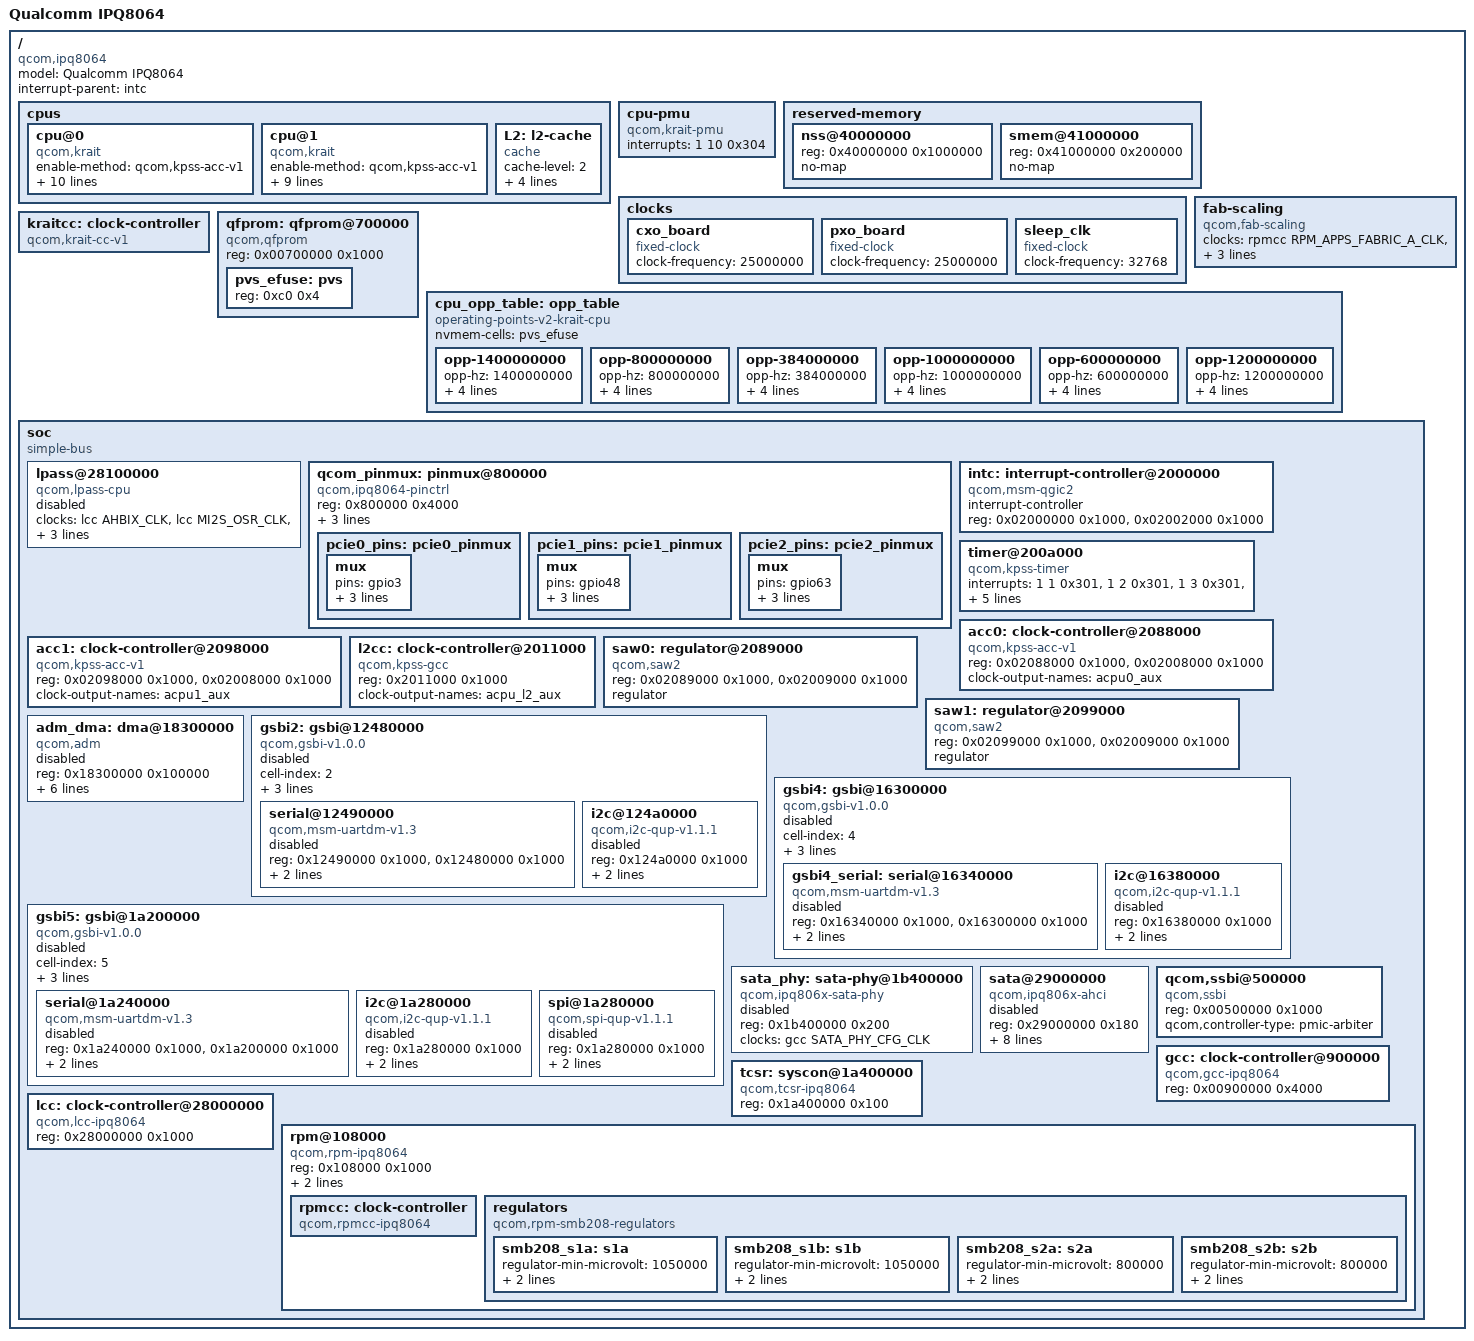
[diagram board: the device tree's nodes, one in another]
/dts-v1/;

#include "skeleton.dtsi"
#include <dt-bindings/clock/qcom,gcc-ipq806x.h>
#include <dt-bindings/clock/qcom,lcc-ipq806x.h>
#include <dt-bindings/reset/qcom,gcc-ipq806x.h>
#include <dt-bindings/soc/qcom,gsbi.h>
#include <dt-bindings/interrupt-controller/arm-gic.h>
#include <dt-bindings/reset/qcom,gcc-ipq806x.h>
#include <dt-bindings/gpio/gpio.h>
#include <dt-bindings/mfd/qcom-rpm.h>
#include <dt-bindings/clock/qcom,rpmcc.h>
/ {
	model = "Qualcomm IPQ8064";
	compatible = "qcom,ipq8064";
	interrupt-parent = <&intc>;

	cpus {
		#address-cells = <1>;
		#size-cells = <0>;

		cpu@0 {
			compatible = "qcom,krait";
			enable-method = "qcom,kpss-acc-v1";
			device_type = "cpu";
			reg = <0>;
			next-level-cache = <&L2>;
			qcom,acc = <&acc0>;
			qcom,saw = <&saw0>;
			clocks = <&kraitcc 0>;
			clock-names = "cpu";
			clock-latency = <100000>;
			cpu-supply = <&smb208_s2a>;
			voltage-tolerance = <5>;
			cpu_fab_threshold = <1000000000>;
			operating-points-v2 = <&cpu_opp_table>;
		};

		cpu@1 {
			compatible = "qcom,krait";
			enable-method = "qcom,kpss-acc-v1";
			device_type = "cpu";
			reg = <1>;
			next-level-cache = <&L2>;
			qcom,acc = <&acc1>;
			qcom,saw = <&saw1>;
			clocks = <&kraitcc 1>;
			clock-names = "cpu";
			clock-latency = <100000>;
			cpu-supply = <&smb208_s2b>;
			cpu_fab_threshold = <1000000000>;
			operating-points-v2 = <&cpu_opp_table>;
		};

		L2: l2-cache {
			compatible = "cache";
			cache-level = <2>;
			clocks = <&kraitcc 4>;
			clock-names = "cache";
			cache-points-kHz = <
				/* kHz    uV    CPU kHz */
				1200000 1150000 1200000
				1000000 1100000  600000
				 384000 1100000  384000
			>;
			vdd_dig-supply = <&smb208_s1a>;
		};
	};

	cpu-pmu {
		compatible = "qcom,krait-pmu";
		interrupts = <1 10 0x304>;
	};

	reserved-memory {
		#address-cells = <1>;
		#size-cells = <1>;
		ranges;

		nss@40000000 {
			reg = <0x40000000 0x1000000>;
			no-map;
		};

		smem@41000000 {
			reg = <0x41000000 0x200000>;
			no-map;
		};
	};

	clocks {
		cxo_board {
			compatible = "fixed-clock";
			#clock-cells = <0>;
			clock-frequency = <25000000>;
		};

		pxo_board {
			compatible = "fixed-clock";
			#clock-cells = <0>;
			clock-frequency = <25000000>;
		};

		sleep_clk: sleep_clk {
			compatible = "fixed-clock";
			clock-frequency = <32768>;
			#clock-cells = <0>;
		};
	};

	fab-scaling {
		compatible = "qcom,fab-scaling";
		clocks = <&rpmcc RPM_APPS_FABRIC_A_CLK>, <&rpmcc RPM_EBI1_A_CLK>;
		clock-names = "apps-fab-clk", "ddr-fab-clk";
		fab_freq_high = <533000000>;
		fab_freq_nominal = <400000000>;
	};

	kraitcc: clock-controller {
		compatible = "qcom,krait-cc-v1";
		#clock-cells = <1>;
	};

	qfprom: qfprom@700000 {
		compatible      = "qcom,qfprom";
		reg	     = <0x00700000 0x1000>;
		#address-cells  = <1>;
		#size-cells     = <1>;
		ranges;
		/* len = 0x4 for FORMAT A */
		pvs_efuse: pvs {
			reg = <0xc0 0x4>;
		};
	};

	cpu_opp_table: opp_table {
		compatible = "operating-points-v2-krait-cpu";
		nvmem-cells = <&pvs_efuse>;

		/*
		 * Missing opp-shared property means CPUs switch DVFS states
		 * independently.
		 */

		opp-1400000000 {
			opp-hz = /bits/ 64 <1400000000>;
			opp-microvolt-speed0-pvs0-v0 = <1250000>;
			opp-microvolt-speed0-pvs1-v0 = <1175000>;
			opp-microvolt-speed0-pvs2-v0 = <1125000>;
			opp-microvolt-speed0-pvs3-v0 = <1050000>;
		};

		opp-800000000 {
			opp-hz = /bits/ 64 <800000000>;
			opp-microvolt-speed0-pvs0-v0 = <1100000>;
			opp-microvolt-speed0-pvs1-v0 = <1025000>;
			opp-microvolt-speed0-pvs2-v0 = <995000>;
			opp-microvolt-speed0-pvs3-v0 = <900000>;
		};

		opp-384000000 {
			opp-hz = /bits/ 64 <384000000>;
			opp-microvolt-speed0-pvs0-v0 = <1000000>;
			opp-microvolt-speed0-pvs1-v0 = <925000>;
			opp-microvolt-speed0-pvs2-v0 = <875000>;
			opp-microvolt-speed0-pvs3-v0 = <800000>;
		};

		opp-1000000000 {
			opp-hz = /bits/ 64 <1000000000>;
			opp-microvolt-speed0-pvs0-v0 = <1150000>;
			opp-microvolt-speed0-pvs1-v0 = <1075000>;
			opp-microvolt-speed0-pvs2-v0 = <1025000>;
			opp-microvolt-speed0-pvs3-v0 = <950000>;
		};

		opp-600000000 {
			opp-hz = /bits/ 64 <600000000>;
			opp-microvolt-speed0-pvs0-v0 = <1050000>;
			opp-microvolt-speed0-pvs1-v0 = <975000>;
			opp-microvolt-speed0-pvs2-v0 = <925000>;
			opp-microvolt-speed0-pvs3-v0 = <850000>;
		};

		opp-1200000000 {
			opp-hz = /bits/ 64 <1200000000>;
			opp-microvolt-speed0-pvs0-v0 = <1200000>;
			opp-microvolt-speed0-pvs1-v0 = <1125000>;
			opp-microvolt-speed0-pvs2-v0 = <1075000>;
			opp-microvolt-speed0-pvs3-v0 = <1000000>;
		};
	};

	soc: soc {
		#address-cells = <1>;
		#size-cells = <1>;
		ranges;
		compatible = "simple-bus";

		lpass@28100000 {
			compatible = "qcom,lpass-cpu";
			status = "disabled";
			clocks = <&lcc AHBIX_CLK>,
					<&lcc MI2S_OSR_CLK>,
					<&lcc MI2S_BIT_CLK>;
			clock-names = "ahbix-clk",
					"mi2s-osr-clk",
					"mi2s-bit-clk";
			interrupts = <0 85 1>;
			interrupt-names = "lpass-irq-lpaif";
			reg = <0x28100000 0x10000>;
			reg-names = "lpass-lpaif";
		};

		qcom_pinmux: pinmux@800000 {
			compatible = "qcom,ipq8064-pinctrl";
			reg = <0x800000 0x4000>;

			gpio-controller;
			#gpio-cells = <2>;
			interrupt-controller;
			#interrupt-cells = <2>;
			interrupts = <0 16 0x4>;

			pcie0_pins: pcie0_pinmux {
				mux {
					pins = "gpio3";
					function = "pcie1_rst";
					drive-strength = <12>;
					bias-disable;
				};
			};

			pcie1_pins: pcie1_pinmux {
				mux {
					pins = "gpio48";
					function = "pcie2_rst";
					drive-strength = <12>;
					bias-disable;
				};
			};

			pcie2_pins: pcie2_pinmux {
				mux {
					pins = "gpio63";
					function = "pcie3_rst";
					drive-strength = <12>;
					bias-disable;
				};
			};
		};

		intc: interrupt-controller@2000000 {
			compatible = "qcom,msm-qgic2";
			interrupt-controller;
			#interrupt-cells = <3>;
			reg = <0x02000000 0x1000>,
			      <0x02002000 0x1000>;
		};

		timer@200a000 {
			compatible = "qcom,kpss-timer",
				     "qcom,kpss-wdt-ipq8064", "qcom,msm-timer";
			interrupts = <1 1 0x301>,
				     <1 2 0x301>,
				     <1 3 0x301>,
				     <1 4 0x301>,
				     <1 5 0x301>;
			reg = <0x0200a000 0x100>;
			clock-frequency = <25000000>,
					  <32768>;
			clocks = <&sleep_clk>;
			clock-names = "sleep";
			cpu-offset = <0x80000>;
		};

		acc0: clock-controller@2088000 {
			compatible = "qcom,kpss-acc-v1";
			reg = <0x02088000 0x1000>, <0x02008000 0x1000>;
			clock-output-names = "acpu0_aux";
		};

		acc1: clock-controller@2098000 {
			compatible = "qcom,kpss-acc-v1";
			reg = <0x02098000 0x1000>, <0x02008000 0x1000>;
			clock-output-names = "acpu1_aux";
		};

		l2cc: clock-controller@2011000 {
			compatible = "qcom,kpss-gcc", "syscon";
			reg = <0x2011000 0x1000>;
			clock-output-names = "acpu_l2_aux";
		};

		saw0: regulator@2089000 {
			compatible = "qcom,saw2";
			reg = <0x02089000 0x1000>, <0x02009000 0x1000>;
			regulator;
		};

		saw1: regulator@2099000 {
			compatible = "qcom,saw2";
			reg = <0x02099000 0x1000>, <0x02009000 0x1000>;
			regulator;
		};

		adm_dma: dma@18300000 {
			compatible = "qcom,adm";
			reg = <0x18300000 0x100000>;
			interrupts = <0 170 0>;
			#dma-cells = <1>;

			clocks = <&gcc ADM0_CLK>, <&gcc ADM0_PBUS_CLK>;
			clock-names = "core", "iface";

			resets = <&gcc ADM0_RESET>,
				 <&gcc ADM0_PBUS_RESET>,
				 <&gcc ADM0_C0_RESET>,
				 <&gcc ADM0_C1_RESET>,
				 <&gcc ADM0_C2_RESET>;
			reset-names = "clk", "pbus", "c0", "c1", "c2";
			qcom,ee = <0>;

			status = "disabled";
		};

		gsbi2: gsbi@12480000 {
			compatible = "qcom,gsbi-v1.0.0";
			cell-index = <2>;
			reg = <0x12480000 0x100>;
			clocks = <&gcc GSBI2_H_CLK>;
			clock-names = "iface";
			#address-cells = <1>;
			#size-cells = <1>;
			ranges;
			status = "disabled";

			syscon-tcsr = <&tcsr>;

			serial@12490000 {
				compatible = "qcom,msm-uartdm-v1.3", "qcom,msm-uartdm";
				reg = <0x12490000 0x1000>,
				      <0x12480000 0x1000>;
				interrupts = <0 195 0x0>;
				clocks = <&gcc GSBI2_UART_CLK>, <&gcc GSBI2_H_CLK>;
				clock-names = "core", "iface";
				status = "disabled";
			};

			i2c@124a0000 {
				compatible = "qcom,i2c-qup-v1.1.1";
				reg = <0x124a0000 0x1000>;
				interrupts = <0 196 0>;

				clocks = <&gcc GSBI2_QUP_CLK>, <&gcc GSBI2_H_CLK>;
				clock-names = "core", "iface";
				status = "disabled";

				#address-cells = <1>;
				#size-cells = <0>;
			};

		};

		gsbi4: gsbi@16300000 {
			compatible = "qcom,gsbi-v1.0.0";
			cell-index = <4>;
			reg = <0x16300000 0x100>;
			clocks = <&gcc GSBI4_H_CLK>;
			clock-names = "iface";
			#address-cells = <1>;
			#size-cells = <1>;
			ranges;
			status = "disabled";

			syscon-tcsr = <&tcsr>;

			gsbi4_serial: serial@16340000 {
				compatible = "qcom,msm-uartdm-v1.3", "qcom,msm-uartdm";
				reg = <0x16340000 0x1000>,
				      <0x16300000 0x1000>;
				interrupts = <0 152 0x0>;
				clocks = <&gcc GSBI4_UART_CLK>, <&gcc GSBI4_H_CLK>;
				clock-names = "core", "iface";
				status = "disabled";
			};

			i2c@16380000 {
				compatible = "qcom,i2c-qup-v1.1.1";
				reg = <0x16380000 0x1000>;
				interrupts = <0 153 0>;

				clocks = <&gcc GSBI4_QUP_CLK>, <&gcc GSBI4_H_CLK>;
				clock-names = "core", "iface";
				status = "disabled";

				#address-cells = <1>;
				#size-cells = <0>;
			};
		};

		gsbi5: gsbi@1a200000 {
			compatible = "qcom,gsbi-v1.0.0";
			cell-index = <5>;
			reg = <0x1a200000 0x100>;
			clocks = <&gcc GSBI5_H_CLK>;
			clock-names = "iface";
			#address-cells = <1>;
			#size-cells = <1>;
			ranges;
			status = "disabled";

			syscon-tcsr = <&tcsr>;

			serial@1a240000 {
				compatible = "qcom,msm-uartdm-v1.3", "qcom,msm-uartdm";
				reg = <0x1a240000 0x1000>,
				      <0x1a200000 0x1000>;
				interrupts = <0 154 0x0>;
				clocks = <&gcc GSBI5_UART_CLK>, <&gcc GSBI5_H_CLK>;
				clock-names = "core", "iface";
				status = "disabled";
			};

			i2c@1a280000 {
				compatible = "qcom,i2c-qup-v1.1.1";
				reg = <0x1a280000 0x1000>;
				interrupts = <0 155 0>;

				clocks = <&gcc GSBI5_QUP_CLK>, <&gcc GSBI5_H_CLK>;
				clock-names = "core", "iface";
				status = "disabled";

				#address-cells = <1>;
				#size-cells = <0>;
			};

			spi@1a280000 {
				compatible = "qcom,spi-qup-v1.1.1";
				reg = <0x1a280000 0x1000>;
				interrupts = <0 155 0>;

				clocks = <&gcc GSBI5_QUP_CLK>, <&gcc GSBI5_H_CLK>;
				clock-names = "core", "iface";
				status = "disabled";

				#address-cells = <1>;
				#size-cells = <0>;
			};
		};

		sata_phy: sata-phy@1b400000 {
			compatible = "qcom,ipq806x-sata-phy";
			reg = <0x1b400000 0x200>;

			clocks = <&gcc SATA_PHY_CFG_CLK>;
			clock-names = "cfg";

			#phy-cells = <0>;
			status = "disabled";
		};

		sata@29000000 {
			compatible = "qcom,ipq806x-ahci", "generic-ahci";
			reg = <0x29000000 0x180>;

			interrupts = <0 209 0x0>;

			clocks = <&gcc SFAB_SATA_S_H_CLK>,
				 <&gcc SATA_H_CLK>,
				 <&gcc SATA_A_CLK>,
				 <&gcc SATA_RXOOB_CLK>,
				 <&gcc SATA_PMALIVE_CLK>;
			clock-names = "slave_face", "iface", "core",
					"rxoob", "pmalive";

			assigned-clocks = <&gcc SATA_RXOOB_CLK>, <&gcc SATA_PMALIVE_CLK>;
			assigned-clock-rates = <100000000>, <100000000>;

			phys = <&sata_phy>;
			phy-names = "sata-phy";
			status = "disabled";
		};

		qcom,ssbi@500000 {
			compatible = "qcom,ssbi";
			reg = <0x00500000 0x1000>;
			qcom,controller-type = "pmic-arbiter";
		};

		gcc: clock-controller@900000 {
			compatible = "qcom,gcc-ipq8064";
			reg = <0x00900000 0x4000>;
			#clock-cells = <1>;
			#reset-cells = <1>;
		};

		tcsr: syscon@1a400000 {
			compatible = "qcom,tcsr-ipq8064", "syscon";
			reg = <0x1a400000 0x100>;
		};

		lcc: clock-controller@28000000 {
			compatible = "qcom,lcc-ipq8064";
			reg = <0x28000000 0x1000>;
			#clock-cells = <1>;
			#reset-cells = <1>;
		};

		rpm@108000 {
			compatible = "qcom,rpm-ipq8064";
			reg = <0x108000 0x1000>;
			qcom,ipc = <&l2cc 0x8 2>;

			interrupts = <0 19 0>,
				     <0 21 0>,
				     <0 22 0>;
			interrupt-names = "ack",
					  "err",
					  "wakeup";

			#address-cells = <1>;
			#size-cells = <0>;

			rpmcc: clock-controller {
				compatible = "qcom,rpmcc-ipq8064", "qcom,rpmcc";
				#clock-cells = <1>;
		        };

			regulators {
				compatible = "qcom,rpm-smb208-regulators";
				smb208_s1a: s1a {
					regulator-min-microvolt = <1050000>;
					regulator-max-microvolt = <1150000>;

					qcom,switch-mode-frequency = <1200000>;
				};

				smb208_s1b: s1b {
					regulator-min-microvolt = <1050000>;
					regulator-max-microvolt = <1150000>;

					qcom,switch-mode-frequency = <1200000>;
				};

				smb208_s2a: s2a {
					regulator-min-microvolt = < 800000>;
					regulator-max-microvolt = <1250000>;

					qcom,switch-mode-frequency = <1200000>;
				};

				smb208_s2b: s2b {
					regulator-min-microvolt = < 800000>;
					regulator-max-microvolt = <1250000>;

					qcom,switch-mode-frequency = <1200000>;
				};
			};
		};
	};
};
